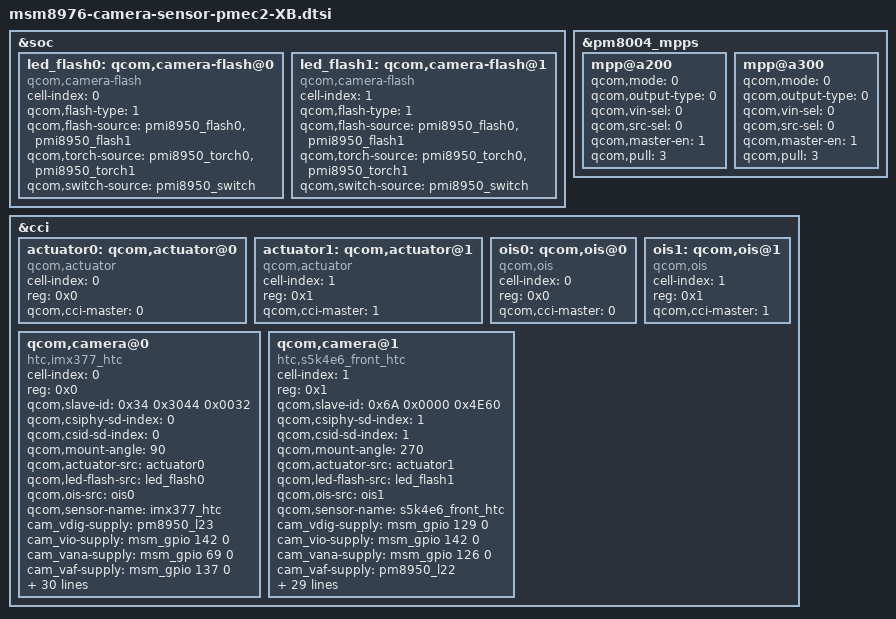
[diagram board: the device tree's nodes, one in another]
/*
 * Copyright (c) 2015, The Linux Foundation. All rights reserved.
 *
 * This program is free software; you can redistribute it and/or modify
 * it under the terms of the GNU General Public License version 2 and
 * only version 2 as published by the Free Software Foundation.
 *
 * This program is distributed in the hope that it will be useful,
 * but WITHOUT ANY WARRANTY; without even the implied warranty of
 * MERCHANTABILITY or FITNESS FOR A PARTICULAR PURPOSE.  See the
 * GNU General Public License for more details.
 */

&soc {
	led_flash0: qcom,camera-flash@0 {
		cell-index = <0>;
		compatible = "qcom,camera-flash";
		qcom,flash-type = <1>;
		qcom,flash-source = <&pmi8950_flash0 &pmi8950_flash1>;
		qcom,torch-source = <&pmi8950_torch0 &pmi8950_torch1>;
		qcom,switch-source = <&pmi8950_switch>;
	};

	led_flash1: qcom,camera-flash@1 {
		cell-index = <1>;
		compatible = "qcom,camera-flash";
		qcom,flash-type = <1>;
		qcom,flash-source = <&pmi8950_flash0 &pmi8950_flash1>;
		qcom,torch-source = <&pmi8950_torch0 &pmi8950_torch1>;
		qcom,switch-source = <&pmi8950_switch>;
	};
};

&pm8004_mpps {
	mpp@a200 { /* PM8004 MPP3 */
		/* Main cam ID */
		qcom,mode = <0>;                /* Digital inout */
		qcom,output-type = <0>;         /* CMOS logic */
		qcom,vin-sel = <0>;             /* VPH_PWR */
		qcom,src-sel = <0>;             /* Constant */
		qcom,master-en = <1>;           /* Enable MPP */
		qcom,pull = <3>;                /*QPNP_PIN_MPP_PULL_UP_30KOHM*/
	};
	mpp@a300 { /* PM8004 MPP4 */
		/* Front cma ID */
		qcom,mode = <0>;                /* Digital inout */
		qcom,output-type = <0>;         /* CMOS logic */
		qcom,vin-sel = <0>;             /* VPH_PWR */
		qcom,src-sel = <0>;             /* Constant */
		qcom,master-en = <1>;           /* Enable MPP */
		qcom,pull = <3>;                /*QPNP_PIN_MPP_PULL_UP_30KOHM*/
	};
};

&cci {
	actuator0: qcom,actuator@0 {
		cell-index = <0>;
		reg = <0x0>;
		compatible = "qcom,actuator";
		qcom,cci-master = <0>;
	};

	actuator1: qcom,actuator@1 {
		cell-index = <1>;
		reg = <0x1>;
		compatible = "qcom,actuator";
		qcom,cci-master = <1>;
	};

	ois0: qcom,ois@0 {
		cell-index = <0>;
		reg = <0x0>;
		compatible = "qcom,ois";
		qcom,cci-master = <0>;
	};

	ois1: qcom,ois@1 {
		cell-index = <1>;
		reg = <0x1>;
		compatible = "qcom,ois";
		qcom,cci-master = <1>;
	};

	qcom,camera@0 {
		cell-index = <0>;
		compatible = "htc,imx377_htc";
		reg = <0x0>;
		qcom,slave-id = <0x34 0x3044 0x0032>;
		//qcom,slave-id = <0x34 0x3912 0x0277>;
		qcom,csiphy-sd-index = <0>;
		qcom,csid-sd-index = <0>;
		qcom,mount-angle = <90>;
		qcom,actuator-src = <&actuator0>;
		qcom,led-flash-src = <&led_flash0>;
		qcom,ois-src = <&ois0>;
		qcom,sensor-name = "imx377_htc";
		cam_vdig-supply = <&pm8950_l23>;
		cam_vio-supply = <&msm_gpio 142 0>;
		cam_vana-supply =<&msm_gpio 69 0>;
		cam_vaf-supply = <&msm_gpio 137 0>;
		qcom,cam-vreg-name = "cam_vdig", "cam_vio", "cam_vana", "cam_vaf";
		qcom,cam-vreg-type = <0 2 2 2>;
		qcom,cam-vreg-min-voltage = <1200000 0 0 2850000>;
		qcom,cam-vreg-max-voltage = <1200000 0 0 2850000>;
		qcom,cam-vreg-op-mode = <212000 7000 0 0>;
		qcom,cam-vreg-gpios-index = <99 4 5 3>;
		qcom,gpio-no-mux = <0>;//
		flash_rw = <&msm_gpio 55 0>;
		pinctrl-names = "cam_default", "cam_suspend";
		pinctrl-0 = <&cam_sensor_mclk0_default &cam_sensor_rear_default &OIS_flash_rw_default>;
		pinctrl-1 = <&cam_sensor_mclk0_sleep &cam_sensor_rear_sleep &OIS_flash_rw_sleep>;
		gpios = <&msm_gpio 26 0>,
			<&msm_gpio 112 0>,
			<&msm_gpio 36 0>,
			<&msm_gpio 137 0>,
			<&msm_gpio 142 0>,
			<&msm_gpio 69 0>;
		qcom,gpio-reset = <1>;
		qcom,gpio-standby = <2>;
		qcom,gpio-req-tbl-num = <0 1 2 3 4 5>;
		qcom,gpio-req-tbl-flags = <1 0 0 0 0 0>;
		qcom,gpio-req-tbl-label = "CAMIF_MCLK0",
			"CAM_RESET0",
			"CAM_STANDBY0",
			"CAM_VCM_EN",
			"CAM_IO_EN",
			"CAM_ANA_EN";
		qcom,csi-lane-assign = <0x4320>;
		qcom,csi-lane-mask = <0x1F>;
		qcom,sensor-position = <0>;
		qcom,sensor-mode = <1>;
		qcom,cci-master = <0>;
		status = "ok";
		clocks = <&clock_gcc clk_mclk0_clk_src>,
				<&clock_gcc clk_gcc_camss_mclk0_clk>;
		clock-names = "cam_src_clk", "cam_clk";
	};

	qcom,camera@1 {
		cell-index = <1>;
		compatible = "htc,s5k4e6_front_htc";
		reg = <0x1>;
		qcom,slave-id = <0x6A 0x0000 0x4E60>;
		qcom,csiphy-sd-index = <1>;
		qcom,csid-sd-index = <1>;
		qcom,mount-angle = <270>;
		qcom,actuator-src = <&actuator1>;
		qcom,led-flash-src = <&led_flash1>;
		qcom,ois-src = <&ois1>;
		qcom,sensor-name = "s5k4e6_front_htc";
		cam_vdig-supply = <&msm_gpio 129 0>;
		cam_vio-supply  = <&msm_gpio 142 0>;
		cam_vana-supply = <&msm_gpio 126 0>;
		cam_vaf-supply = <&pm8950_l22>;
		qcom,cam-vreg-name = "cam_vdig", "cam_vio", "cam_vana", "cam_vaf";
		qcom,cam-vreg-type = <2 2 2 0>;
		qcom,cam-vreg-min-voltage = <0 0 0 2850000>;
		qcom,cam-vreg-max-voltage = <0 0 0 2850000>;
		qcom,cam-vreg-op-mode = <0 0 0 91000>;
		qcom,cam-vreg-gpios-index = <5 3 4 99>;
		qcom,gpio-no-mux = <0>;
		flash_rw = <&msm_gpio 31 0>;
		pinctrl-names = "cam_default", "cam_suspend";
		pinctrl-0 = <&cam_sensor_mclk1_default &cam_sensor_front_default>;
		pinctrl-1 = <&cam_sensor_mclk1_sleep &cam_sensor_front_sleep>;
		gpios = <&msm_gpio 27 0>,
			<&msm_gpio 34 0>,
			<&msm_gpio 128 0>,
			<&msm_gpio 142 0>,
			<&msm_gpio 126 0>,
			<&msm_gpio 129 0>;
		qcom,gpio-reset = <1>;
		qcom,gpio-standby = <2>;
		qcom,gpio-req-tbl-num = <0 1 2 3 4 5>;
		qcom,gpio-req-tbl-flags = <1 0 0 0 0 0>;
		qcom,gpio-req-tbl-label = "CAMIF_MCLK1",
			"CAM_RESET1",
			"CAM_STANDBY1",
			"CAM_IO_EN1",
			"CAM_A2V8_EN1",
			"CAM_D1V2_EN1";
		qcom,csi-lane-assign = <0x4320>;
		qcom,csi-lane-mask   = <0x7>; // 2-lane
		qcom,sensor-position = <1>;
		qcom,sensor-mode = <1>;
		qcom,cci-master = <1>;
		status = "ok";
		clocks = <&clock_gcc clk_mclk1_clk_src>,
			<&clock_gcc clk_gcc_camss_mclk1_clk>;
		clock-names = "cam_src_clk", "cam_clk";
	};
};
